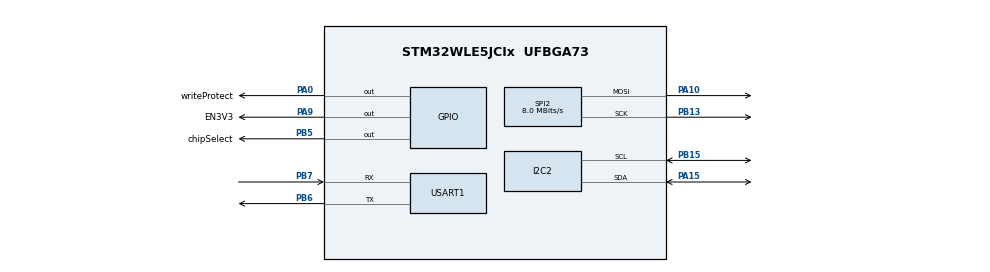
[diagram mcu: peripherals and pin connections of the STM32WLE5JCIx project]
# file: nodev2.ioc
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ADC.Channel-0\#ChannelRegularConversion=ADC_CHANNEL_TEMPSENSOR
ADC.Channel-1\#ChannelRegularConversion=ADC_CHANNEL_VBAT
ADC.ClockPrescaler=ADC_CLOCK_SYNC_PCLK_DIV2
ADC.ContinuousConvMode=DISABLE
ADC.EnableRegularConversion=ENABLE
ADC.NbrOfConversion=2
ADC.NbrOfConversionFlag=1
ADC.Rank-0\#ChannelRegularConversion=1
ADC.Rank-1\#ChannelRegularConversion=2
ADC.SamplingTime-0\#ChannelRegularConversion=ADC_SAMPLINGTIME_COMMON_1
ADC.SamplingTime-1\#ChannelRegularConversion=ADC_SAMPLINGTIME_COMMON_1
ADC.SamplingTimeCommon1=ADC_SAMPLETIME_160CYCLES_5
ADC.SelectedChannel=ADC_CHANNEL_TEMPSENSOR|ADC_CHANNEL_VREFINT|ADC_CHANNEL_VBAT
Dma.ADC.0.Direction=DMA_PERIPH_TO_MEMORY
Dma.ADC.0.EventEnable=DISABLE
Dma.ADC.0.Instance=DMA1_Channel1
Dma.ADC.0.MemDataAlignment=DMA_MDATAALIGN_HALFWORD
Dma.ADC.0.MemInc=DMA_MINC_ENABLE
Dma.ADC.0.Mode=DMA_NORMAL
Dma.ADC.0.PeriphDataAlignment=DMA_PDATAALIGN_HALFWORD
Dma.ADC.0.PeriphInc=DMA_PINC_DISABLE
Dma.ADC.0.Polarity=HAL_DMAMUX_REQ_GEN_RISING
Dma.ADC.0.Priority=DMA_PRIORITY_LOW
Dma.ADC.0.RequestNumber=1
Dma.ADC.0.SignalID=NONE
Dma.ADC.0.SyncEnable=DISABLE
Dma.ADC.0.SyncPolarity=HAL_DMAMUX_SYNC_NO_EVENT
Dma.ADC.0.SyncRequestNumber=1
Dma.ADC.0.SyncSignalID=NONE
Dma.Request0=ADC
Mcu.Family=STM32WL
Mcu.Name=STM32WLE5JCIx
Mcu.Package=UFBGA73
NVIC.DMA1_Channel1_IRQn=true\:0\:0\:false\:false\:true\:false\:true\:true
NVIC.PriorityGroup=NVIC_PRIORITYGROUP_4
PA0.GPIO_Label=writeProtect
PA0.Signal=GPIO_Output
PA10.Mode=TX_Only_Simplex_Unidirect_Master
PA10.Signal=SPI2_MOSI
PA13.Mode=Serial_Wire
PA13.Signal=DEBUG_JTMS-SWDIO
PA14.Mode=Serial_Wire
PA14.Signal=DEBUG_JTCK-SWCLK
PA15.Mode=I2C
PA15.Signal=I2C2_SDA
PA9.GPIO_Label=EN3V3
PA9.Signal=GPIO_Output
PB13.Mode=TX_Only_Simplex_Unidirect_Master
PB13.Signal=SPI2_SCK
PB15.Mode=I2C
PB15.Signal=I2C2_SCL
PB5.GPIO_Label=chipSelect
PB5.Signal=GPIO_Output
PB6.Mode=Asynchronous
PB6.Signal=USART1_TX
PB7.Mode=Asynchronous
PB7.Signal=USART1_RX
ProjectManager.HeapSize=0x200
ProjectManager.StackSize=0x400
ProjectManager.TargetToolchain=STM32CubeIDE
RCC.AHBFreq_Value=4000000
RCC.APB1Freq_Value=4000000
RCC.APB1TimFreq_Value=4000000
RCC.APB2Freq_Value=4000000
RCC.APB2TimFreq_Value=4000000
RCC.APB3Freq_Value=4000000
RCC.CortexFreq_Value=4000000
RCC.HCLKFreq_Value=4000000
RCC.HSE_VALUE=8000000
RCC.HSI_VALUE=16000000
RCC.LSE_VALUE=32768
RCC.SYSCLKFreq_VALUE=4000000
RCC.VCOOutputFreq_Value=32000000
SPI2.CalculateBaudRate=8.0 MBits/s
SPI2.Direction=SPI_DIRECTION_2LINES
SPI2.Mode=SPI_MODE_MASTER
SPI2.VirtualType=VM_MASTER
USART1.VirtualMode-Asynchronous=VM_ASYNC
VP_ADC_TempSens_Input.Mode=IN-TempSens
VP_ADC_Vbat_Input.Mode=IN-Vbat
VP_ADC_Vref_Input.Mode=IN-Vrefint
VP_RTC_VS_RTC_Activate.Mode=RTC_Enabled
VP_RTC_VS_RTC_WakeUp_intern.Mode=WakeUp
board=custom

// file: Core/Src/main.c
/* USER CODE BEGIN Header */
/**
 ******************************************************************************
 * @file           : main.c
 * @brief          : Main program body
 ******************************************************************************
 * @attention
 *
 * Copyright (c) 2023 STMicroelectronics.
 * All rights reserved.
 *
 * This software is licensed under terms that can be found in the LICENSE file
 * in the root directory of this software component.
 * If no LICENSE file comes with this software, it is provided AS-IS.
 *
 ******************************************************************************
 */
/* USER CODE END Header */
#include "main.h"

/* USER CODE BEGIN Includes */
#include "stdio.h"
/* USER CODE END Includes */

ADC_HandleTypeDef hadc;
DMA_HandleTypeDef hdma_adc;

I2C_HandleTypeDef hi2c2;

RTC_HandleTypeDef hrtc;

SPI_HandleTypeDef hspi2;

UART_HandleTypeDef huart1;

/* USER CODE BEGIN PV */

uint16_t adcResults[2];

/* USER CODE END PV */

void SystemClock_Config(void);
static void MX_GPIO_Init(void);
static void MX_DMA_Init(void);
static void MX_ADC_Init(void);
static void MX_RTC_Init(void);
static void MX_SPI2_Init(void);
static void MX_USART1_UART_Init(void);
static void MX_I2C2_Init(void);

int main(void) {

    /* MCU Configuration--------------------------------------------------------*/

    /* Reset of all peripherals, Initializes the Flash interface and the Systick. */
    HAL_Init();

    /* Configure the system clock */
    SystemClock_Config();

    /* Initialize all configured peripherals */
    MX_GPIO_Init();
    MX_DMA_Init();
    MX_ADC_Init();
    MX_RTC_Init();
    MX_SPI2_Init();
    MX_USART1_UART_Init();
    MX_I2C2_Init();
    /* USER CODE BEGIN 2 */

    uint8_t StartMSG[] = "Start I2C Scan New:\n";
    uint8_t EndMSG[]   = "Ready\n";
    uint8_t Buffer[10];
    HAL_GPIO_WritePin(EN3V3_GPIO_Port, EN3V3_Pin, 1U);        // Enabling 3.3V on the board...

    HAL_Delay(1000);

    HAL_ADCEx_Calibration_Start(&hadc);

    /* USER CODE END 2 */

    /* Infinite loop */
    /* USER CODE BEGIN WHILE */
    while (1) {
        // HAL_GPIO_TogglePin(chipSelect_GPIO_Port, chipSelect_Pin);
        /*	  HAL_GPIO_WritePin(SDA_GPIO_Port, SDA_Pin, 1U);
              HAL_Delay(10U);
              HAL_GPIO_WritePin(SDA_GPIO_Port, SDA_Pin, 0U);
              HAL_GPIO_WritePin(SCL_GPIO_Port, SCL_Pin, 1U);
              HAL_Delay(10U);
              HAL_GPIO_WritePin(SCL_GPIO_Port, SCL_Pin, 0U);
        */
        HAL_ADC_Start_DMA(&hadc, adcResults, 2);
        uint32_t uniqueId0 =         LL_GetUID_Word0();
        uint32_t uniqueId1 =         LL_GetUID_Word1();
        uint32_t uniqueId2 =         LL_GetUID_Word2();

        //SYS_GetBatteryLevel(void);

        // HAL_ADC_PollForConversion(&hadc, 100);
        // uint32_t adcResult = HAL_ADC_GetValue(&hadc);

        // HAL_UART_Transmit(&huart1, StartMSG, 17, 10000);
        // HAL_Delay(100U);

        /*	  for(uint8_t i=1; i<128; i++)
                  {
                  if (HAL_I2C_IsDeviceReady(&hi2c2, (uint16_t)(i<<1), 3, 5) == HAL_OK) {

                      sprintf(Buffer, "0x%2X, ", i);
                                  HAL_UART_Transmit(&huart1, Buffer, 5, 10000);

                      } else {

                      }
                      //if (i > 0 && (i + 1) % 16 == 0) printf("\n");
                  }

        */
        // HAL_UART_Transmit(&huart1, EndMSG, 6, 10000);

        HAL_Delay(1000U);

        // HAL_UART_Transmit(&huart1, ".", 1, 100U);
        /* USER CODE END WHILE */

    }
}

void SystemClock_Config(void) {
    RCC_OscInitTypeDef RCC_OscInitStruct = {0};
    RCC_ClkInitTypeDef RCC_ClkInitStruct = {0};

    /** Configure the main internal regulator output voltage
     */
    __HAL_PWR_VOLTAGESCALING_CONFIG(PWR_REGULATOR_VOLTAGE_SCALE2);

    /** Initializes the CPU, AHB and APB buses clocks
     */
    RCC_OscInitStruct.OscillatorType      = RCC_OSCILLATORTYPE_HSI | RCC_OSCILLATORTYPE_LSI | RCC_OSCILLATORTYPE_MSI;
    RCC_OscInitStruct.HSIState            = RCC_HSI_ON;
    RCC_OscInitStruct.MSIState            = RCC_MSI_ON;
    RCC_OscInitStruct.HSICalibrationValue = RCC_HSICALIBRATION_DEFAULT;
    RCC_OscInitStruct.MSICalibrationValue = RCC_MSICALIBRATION_DEFAULT;
    RCC_OscInitStruct.MSIClockRange       = RCC_MSIRANGE_6;
    RCC_OscInitStruct.LSIDiv              = RCC_LSI_DIV1;
    RCC_OscInitStruct.LSIState            = RCC_LSI_ON;
    RCC_OscInitStruct.PLL.PLLState        = RCC_PLL_NONE;
    if (HAL_RCC_OscConfig(&RCC_OscInitStruct) != HAL_OK) {
        Error_Handler();
    }

    /** Configure the SYSCLKSource, HCLK, PCLK1 and PCLK2 clocks dividers
     */
    RCC_ClkInitStruct.ClockType      = RCC_CLOCKTYPE_HCLK3 | RCC_CLOCKTYPE_HCLK | RCC_CLOCKTYPE_SYSCLK | RCC_CLOCKTYPE_PCLK1 | RCC_CLOCKTYPE_PCLK2;
    RCC_ClkInitStruct.SYSCLKSource   = RCC_SYSCLKSOURCE_MSI;
    RCC_ClkInitStruct.AHBCLKDivider  = RCC_SYSCLK_DIV1;
    RCC_ClkInitStruct.APB1CLKDivider = RCC_HCLK_DIV1;
    RCC_ClkInitStruct.APB2CLKDivider = RCC_HCLK_DIV1;
    RCC_ClkInitStruct.AHBCLK3Divider = RCC_SYSCLK_DIV1;

    if (HAL_RCC_ClockConfig(&RCC_ClkInitStruct, FLASH_LATENCY_0) != HAL_OK) {
        Error_Handler();
    }
}

static void MX_ADC_Init(void) {

    ADC_ChannelConfTypeDef sConfig = {0};

    /** Configure the global features of the ADC (Clock, Resolution, Data Alignment and number of conversion)
     */
    hadc.Instance                   = ADC;
    hadc.Init.ClockPrescaler        = ADC_CLOCK_SYNC_PCLK_DIV2;
    hadc.Init.Resolution            = ADC_RESOLUTION_12B;
    hadc.Init.DataAlign             = ADC_DATAALIGN_RIGHT;
    hadc.Init.ScanConvMode          = ADC_SCAN_ENABLE;
    hadc.Init.EOCSelection          = ADC_EOC_SINGLE_CONV;
    hadc.Init.LowPowerAutoWait      = DISABLE;
    hadc.Init.LowPowerAutoPowerOff  = DISABLE;
    hadc.Init.ContinuousConvMode    = DISABLE;
    hadc.Init.NbrOfConversion       = 2;
    hadc.Init.DiscontinuousConvMode = DISABLE;
    hadc.Init.ExternalTrigConv      = ADC_SOFTWARE_START;
    hadc.Init.ExternalTrigConvEdge  = ADC_EXTERNALTRIGCONVEDGE_NONE;
    hadc.Init.DMAContinuousRequests = DISABLE;
    hadc.Init.Overrun               = ADC_OVR_DATA_PRESERVED;
    hadc.Init.SamplingTimeCommon1   = ADC_SAMPLETIME_160CYCLES_5;
    hadc.Init.SamplingTimeCommon2   = ADC_SAMPLETIME_1CYCLE_5;
    hadc.Init.OversamplingMode      = DISABLE;
    hadc.Init.TriggerFrequencyMode  = ADC_TRIGGER_FREQ_HIGH;
    if (HAL_ADC_Init(&hadc) != HAL_OK) {
        Error_Handler();
    }

    /** Configure Regular Channel
     */
    sConfig.Channel      = ADC_CHANNEL_TEMPSENSOR;
    sConfig.Rank         = ADC_REGULAR_RANK_1;
    sConfig.SamplingTime = ADC_SAMPLINGTIME_COMMON_1;
    if (HAL_ADC_ConfigChannel(&hadc, &sConfig) != HAL_OK) {
        Error_Handler();
    }

    /** Configure Regular Channel
     */
    sConfig.Channel = ADC_CHANNEL_VBAT;
    sConfig.Rank    = ADC_REGULAR_RANK_2;
    if (HAL_ADC_ConfigChannel(&hadc, &sConfig) != HAL_OK) {
        Error_Handler();
    }
}

static void MX_I2C2_Init(void) {

    hi2c2.Instance              = I2C2;
    hi2c2.Init.Timing           = 0x00000E14;
    hi2c2.Init.OwnAddress1      = 0;
    hi2c2.Init.AddressingMode   = I2C_ADDRESSINGMODE_7BIT;
    hi2c2.Init.DualAddressMode  = I2C_DUALADDRESS_DISABLE;
    hi2c2.Init.OwnAddress2      = 0;
    hi2c2.Init.OwnAddress2Masks = I2C_OA2_NOMASK;
    hi2c2.Init.GeneralCallMode  = I2C_GENERALCALL_DISABLE;
    hi2c2.Init.NoStretchMode    = I2C_NOSTRETCH_DISABLE;
    if (HAL_I2C_Init(&hi2c2) != HAL_OK) {
        Error_Handler();
    }

    /** Configure Analogue filter
     */
    if (HAL_I2CEx_ConfigAnalogFilter(&hi2c2, I2C_ANALOGFILTER_ENABLE) != HAL_OK) {
        Error_Handler();
    }

    /** Configure Digital filter
     */
    if (HAL_I2CEx_ConfigDigitalFilter(&hi2c2, 0) != HAL_OK) {
        Error_Handler();
    }
}

static void MX_RTC_Init(void) {

    /** Initialize RTC Only
     */
    hrtc.Instance            = RTC;
    hrtc.Init.HourFormat     = RTC_HOURFORMAT_24;
    hrtc.Init.AsynchPrediv   = 127;
    hrtc.Init.SynchPrediv    = 255;
    hrtc.Init.OutPut         = RTC_OUTPUT_DISABLE;
    hrtc.Init.OutPutRemap    = RTC_OUTPUT_REMAP_NONE;
    hrtc.Init.OutPutPolarity = RTC_OUTPUT_POLARITY_HIGH;
    hrtc.Init.OutPutType     = RTC_OUTPUT_TYPE_OPENDRAIN;
    hrtc.Init.OutPutPullUp   = RTC_OUTPUT_PULLUP_NONE;
    hrtc.Init.BinMode        = RTC_BINARY_NONE;
    if (HAL_RTC_Init(&hrtc) != HAL_OK) {
        Error_Handler();
    }

    /** Enable the WakeUp
     */
    if (HAL_RTCEx_SetWakeUpTimer(&hrtc, 0, RTC_WAKEUPCLOCK_RTCCLK_DIV16) != HAL_OK) {
        Error_Handler();
    }
}

static void MX_SPI2_Init(void) {

    /* SPI2 parameter configuration*/
    hspi2.Instance               = SPI2;
    hspi2.Init.Mode              = SPI_MODE_MASTER;
    hspi2.Init.Direction         = SPI_DIRECTION_2LINES;
    hspi2.Init.DataSize          = SPI_DATASIZE_4BIT;
    hspi2.Init.CLKPolarity       = SPI_POLARITY_LOW;
    hspi2.Init.CLKPhase          = SPI_PHASE_1EDGE;
    hspi2.Init.NSS               = SPI_NSS_SOFT;
    hspi2.Init.BaudRatePrescaler = SPI_BAUDRATEPRESCALER_2;
    hspi2.Init.FirstBit          = SPI_FIRSTBIT_MSB;
    hspi2.Init.TIMode            = SPI_TIMODE_DISABLE;
    hspi2.Init.CRCCalculation    = SPI_CRCCALCULATION_DISABLE;
    hspi2.Init.CRCPolynomial     = 7;
    hspi2.Init.CRCLength         = SPI_CRC_LENGTH_DATASIZE;
    hspi2.Init.NSSPMode          = SPI_NSS_PULSE_ENABLE;
    if (HAL_SPI_Init(&hspi2) != HAL_OK) {
        Error_Handler();
    }
}

static void MX_USART1_UART_Init(void) {

    huart1.Instance                    = USART1;
    huart1.Init.BaudRate               = 115200;
    huart1.Init.WordLength             = UART_WORDLENGTH_8B;
    huart1.Init.StopBits               = UART_STOPBITS_1;
    huart1.Init.Parity                 = UART_PARITY_NONE;
    huart1.Init.Mode                   = UART_MODE_TX_RX;
    huart1.Init.HwFlowCtl              = UART_HWCONTROL_NONE;
    huart1.Init.OverSampling           = UART_OVERSAMPLING_16;
    huart1.Init.OneBitSampling         = UART_ONE_BIT_SAMPLE_DISABLE;
    huart1.Init.ClockPrescaler         = UART_PRESCALER_DIV1;
    huart1.AdvancedInit.AdvFeatureInit = UART_ADVFEATURE_NO_INIT;
    if (HAL_UART_Init(&huart1) != HAL_OK) {
        Error_Handler();
    }
    if (HAL_UARTEx_SetTxFifoThreshold(&huart1, UART_TXFIFO_THRESHOLD_1_8) != HAL_OK) {
        Error_Handler();
    }
    if (HAL_UARTEx_SetRxFifoThreshold(&huart1, UART_RXFIFO_THRESHOLD_1_8) != HAL_OK) {
        Error_Handler();
    }
    if (HAL_UARTEx_DisableFifoMode(&huart1) != HAL_OK) {
        Error_Handler();
    }
}

static void MX_DMA_Init(void) {
    /* DMA controller clock enable */
    __HAL_RCC_DMAMUX1_CLK_ENABLE();
    __HAL_RCC_DMA1_CLK_ENABLE();

    /* DMA interrupt init */
    /* DMA1_Channel1_IRQn interrupt configuration */
    HAL_NVIC_SetPriority(DMA1_Channel1_IRQn, 0, 0);
    HAL_NVIC_EnableIRQ(DMA1_Channel1_IRQn);
}

static void MX_GPIO_Init(void) {
    GPIO_InitTypeDef GPIO_InitStruct = {0};

    /* GPIO Ports Clock Enable */
    __HAL_RCC_GPIOA_CLK_ENABLE();
    __HAL_RCC_GPIOB_CLK_ENABLE();

    /*Configure GPIO pin Output Level */
    HAL_GPIO_WritePin(chipSelect_GPIO_Port, chipSelect_Pin, GPIO_PIN_RESET);

    /*Configure GPIO pin Output Level */
    HAL_GPIO_WritePin(GPIOA, writeProtect_Pin | EN3V3_Pin, GPIO_PIN_RESET);

    /*Configure GPIO pin : chipSelect_Pin */
    GPIO_InitStruct.Pin   = chipSelect_Pin;
    GPIO_InitStruct.Mode  = GPIO_MODE_OUTPUT_PP;
    GPIO_InitStruct.Pull  = GPIO_NOPULL;
    GPIO_InitStruct.Speed = GPIO_SPEED_FREQ_LOW;
    HAL_GPIO_Init(chipSelect_GPIO_Port, &GPIO_InitStruct);

    /*Configure GPIO pins : writeProtect_Pin EN3V3_Pin */
    GPIO_InitStruct.Pin   = writeProtect_Pin | EN3V3_Pin;
    GPIO_InitStruct.Mode  = GPIO_MODE_OUTPUT_PP;
    GPIO_InitStruct.Pull  = GPIO_NOPULL;
    GPIO_InitStruct.Speed = GPIO_SPEED_FREQ_LOW;
    HAL_GPIO_Init(GPIOA, &GPIO_InitStruct);
}

void Error_Handler(void) {
    __disable_irq();
    while (1) {
    }
}
